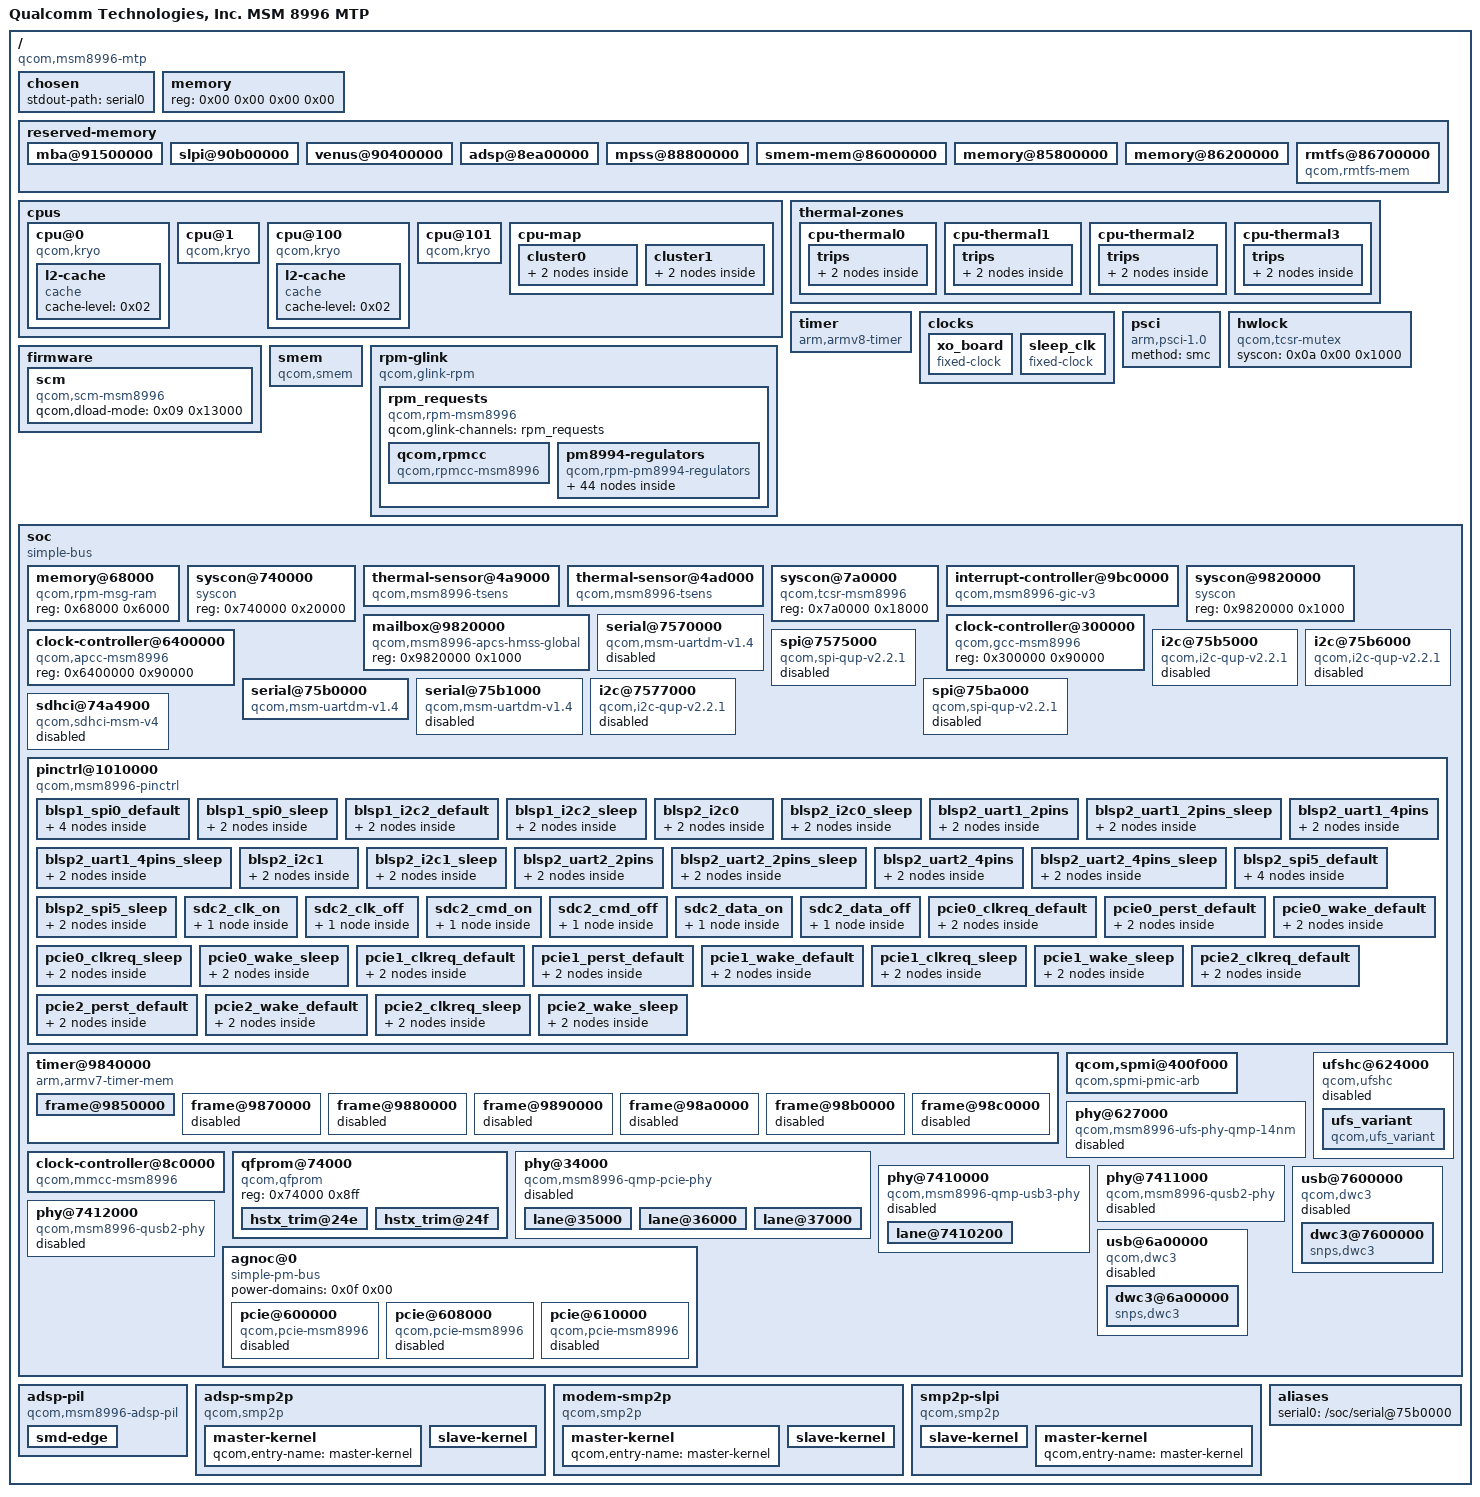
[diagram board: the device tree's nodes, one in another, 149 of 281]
/dts-v1/;

/ {
	model = "Qualcomm Technologies, Inc. MSM 8996 MTP";
	interrupt-parent = <0x01>;
	#address-cells = <0x02>;
	#size-cells = <0x02>;
	compatible = "qcom,msm8996-mtp";

	chosen {
		stdout-path = "serial0";
	};

	memory {
		device_type = "memory";
		reg = <0x00 0x00 0x00 0x00>;
	};

	reserved-memory {
		#address-cells = <0x02>;
		#size-cells = <0x02>;
		ranges;

		mba@91500000 {
			reg = <0x00 0x91500000 0x00 0x200000>;
			no-map;
		};

		slpi@90b00000 {
			reg = <0x00 0x90b00000 0x00 0xa00000>;
			no-map;
		};

		venus@90400000 {
			reg = <0x00 0x90400000 0x00 0x700000>;
			no-map;
		};

		adsp@8ea00000 {
			reg = <0x00 0x8ea00000 0x00 0x1a00000>;
			no-map;
			phandle = <0x3c>;
		};

		mpss@88800000 {
			reg = <0x00 0x88800000 0x00 0x6200000>;
			no-map;
		};

		smem-mem@86000000 {
			reg = <0x00 0x86000000 0x00 0x200000>;
			no-map;
			phandle = <0x0b>;
		};

		memory@85800000 {
			reg = <0x00 0x85800000 0x00 0x800000>;
			no-map;
		};

		memory@86200000 {
			reg = <0x00 0x86200000 0x00 0x2600000>;
			no-map;
		};

		rmtfs@86700000 {
			compatible = "qcom,rmtfs-mem";
			size = <0x00 0x200000>;
			alloc-ranges = <0x00 0xa0000000 0x00 0x2000000>;
			no-map;
			qcom,client-id = <0x01>;
			qcom,vmid = <0x0f>;
		};
	};

	cpus {
		#address-cells = <0x02>;
		#size-cells = <0x00>;

		cpu@0 {
			device_type = "cpu";
			compatible = "qcom,kryo";
			reg = <0x00 0x00>;
			enable-method = "psci";
			next-level-cache = <0x02>;
			phandle = <0x04>;

			l2-cache {
				compatible = "cache";
				cache-level = <0x02>;
				phandle = <0x02>;
			};
		};

		cpu@1 {
			device_type = "cpu";
			compatible = "qcom,kryo";
			reg = <0x00 0x01>;
			enable-method = "psci";
			next-level-cache = <0x02>;
			phandle = <0x05>;
		};

		cpu@100 {
			device_type = "cpu";
			compatible = "qcom,kryo";
			reg = <0x00 0x100>;
			enable-method = "psci";
			next-level-cache = <0x03>;
			phandle = <0x06>;

			l2-cache {
				compatible = "cache";
				cache-level = <0x02>;
				phandle = <0x03>;
			};
		};

		cpu@101 {
			device_type = "cpu";
			compatible = "qcom,kryo";
			reg = <0x00 0x101>;
			enable-method = "psci";
			next-level-cache = <0x03>;
			phandle = <0x07>;
		};

		cpu-map {

			cluster0 {

				core0 {
					cpu = <0x04>;
				};

				core1 {
					cpu = <0x05>;
				};
			};

			cluster1 {

				core0 {
					cpu = <0x06>;
				};

				core1 {
					cpu = <0x07>;
				};
			};
		};
	};

	thermal-zones {

		cpu-thermal0 {
			polling-delay-passive = <0xfa>;
			polling-delay = <0x3e8>;
			thermal-sensors = <0x08 0x03>;

			trips {

				trip0 {
					temperature = <0x124f8>;
					hysteresis = <0x7d0>;
					type = "passive";
				};

				trip1 {
					temperature = <0x1adb0>;
					hysteresis = <0x7d0>;
					type = "critical";
				};
			};
		};

		cpu-thermal1 {
			polling-delay-passive = <0xfa>;
			polling-delay = <0x3e8>;
			thermal-sensors = <0x08 0x05>;

			trips {

				trip0 {
					temperature = <0x124f8>;
					hysteresis = <0x7d0>;
					type = "passive";
				};

				trip1 {
					temperature = <0x1adb0>;
					hysteresis = <0x7d0>;
					type = "critical";
				};
			};
		};

		cpu-thermal2 {
			polling-delay-passive = <0xfa>;
			polling-delay = <0x3e8>;
			thermal-sensors = <0x08 0x08>;

			trips {

				trip0 {
					temperature = <0x124f8>;
					hysteresis = <0x7d0>;
					type = "passive";
				};

				trip1 {
					temperature = <0x1adb0>;
					hysteresis = <0x7d0>;
					type = "critical";
				};
			};
		};

		cpu-thermal3 {
			polling-delay-passive = <0xfa>;
			polling-delay = <0x3e8>;
			thermal-sensors = <0x08 0x0a>;

			trips {

				trip0 {
					temperature = <0x124f8>;
					hysteresis = <0x7d0>;
					type = "passive";
				};

				trip1 {
					temperature = <0x1adb0>;
					hysteresis = <0x7d0>;
					type = "critical";
				};
			};
		};
	};

	timer {
		compatible = "arm,armv8-timer";
		interrupts = <0x01 0x0d 0x08 0x01 0x0e 0x08 0x01 0x0b 0x08 0x01 0x0a 0x08>;
	};

	clocks {

		xo_board {
			compatible = "fixed-clock";
			#clock-cells = <0x00>;
			clock-frequency = <0x124f800>;
			clock-output-names = "xo_board";
			phandle = <0x1a>;
		};

		sleep_clk {
			compatible = "fixed-clock";
			#clock-cells = <0x00>;
			clock-frequency = <0x7ffc>;
			clock-output-names = "sleep_clk";
		};
	};

	psci {
		compatible = "arm,psci-1.0";
		method = "smc";
	};

	firmware {

		scm {
			compatible = "qcom,scm-msm8996";
			qcom,dload-mode = <0x09 0x13000>;
		};
	};

	hwlock {
		compatible = "qcom,tcsr-mutex";
		syscon = <0x0a 0x00 0x1000>;
		#hwlock-cells = <0x01>;
		phandle = <0x0c>;
	};

	smem {
		compatible = "qcom,smem";
		memory-region = <0x0b>;
		hwlocks = <0x0c 0x03>;
	};

	rpm-glink {
		compatible = "qcom,glink-rpm";
		interrupts = <0x00 0xa8 0x01>;
		qcom,rpm-msg-ram = <0x0d>;
		mboxes = <0x0e 0x00>;

		rpm_requests {
			compatible = "qcom,rpm-msm8996";
			qcom,glink-channels = "rpm_requests";

			qcom,rpmcc {
				compatible = "qcom,rpmcc-msm8996";
				#clock-cells = <0x01>;
				phandle = <0x1e>;
			};

			pm8994-regulators {
				compatible = "qcom,rpm-pm8994-regulators";

				s1 {
				};

				s2 {
				};

				s3 {
				};

				s4 {
					phandle = <0x21>;
				};

				s5 {
				};

				s6 {
				};

				s7 {
				};

				s8 {
				};

				s9 {
				};

				s10 {
				};

				s11 {
				};

				s12 {
				};

				l1 {
				};

				l2 {
				};

				l3 {
				};

				l4 {
				};

				l5 {
				};

				l6 {
				};

				l7 {
				};

				l8 {
				};

				l9 {
				};

				l10 {
				};

				l11 {
				};

				l12 {
					phandle = <0x1c>;
				};

				l13 {
				};

				l14 {
				};

				l15 {
				};

				l16 {
				};

				l17 {
				};

				l18 {
				};

				l19 {
				};

				l20 {
					phandle = <0x20>;
				};

				l21 {
				};

				l22 {
				};

				l23 {
				};

				l24 {
					phandle = <0x23>;
				};

				l25 {
					phandle = <0x1d>;
				};

				l26 {
				};

				l27 {
				};

				l28 {
					phandle = <0x1b>;
				};

				l29 {
				};

				l30 {
				};

				l31 {
				};

				l32 {
				};
			};
		};
	};

	soc {
		#address-cells = <0x01>;
		#size-cells = <0x01>;
		ranges = <0x00 0x00 0x00 0xffffffff>;
		compatible = "simple-bus";

		memory@68000 {
			compatible = "qcom,rpm-msg-ram";
			reg = <0x68000 0x6000>;
			phandle = <0x0d>;
		};

		syscon@740000 {
			compatible = "syscon";
			reg = <0x740000 0x20000>;
			phandle = <0x0a>;
		};

		thermal-sensor@4a9000 {
			compatible = "qcom,msm8996-tsens";
			reg = <0x4a9000 0x1000 0x4a8000 0x1000>;
			#qcom,sensors = <0x0d>;
			#thermal-sensor-cells = <0x01>;
			phandle = <0x08>;
		};

		thermal-sensor@4ad000 {
			compatible = "qcom,msm8996-tsens";
			reg = <0x4ad000 0x1000 0x4ac000 0x1000>;
			#qcom,sensors = <0x08>;
			#thermal-sensor-cells = <0x01>;
		};

		syscon@7a0000 {
			compatible = "qcom,tcsr-msm8996\0syscon";
			reg = <0x7a0000 0x18000>;
			phandle = <0x09>;
		};

		interrupt-controller@9bc0000 {
			compatible = "qcom,msm8996-gic-v3\0arm,gic-v3";
			#interrupt-cells = <0x03>;
			interrupt-controller;
			#redistributor-regions = <0x01>;
			redistributor-stride = <0x00 0x40000>;
			reg = <0x9bc0000 0x10000 0x9c00000 0x100000>;
			interrupts = <0x01 0x09 0x04>;
			phandle = <0x01>;
		};

		syscon@9820000 {
			compatible = "syscon";
			reg = <0x9820000 0x1000>;
			phandle = <0x3e>;
		};

		mailbox@9820000 {
			compatible = "qcom,msm8996-apcs-hmss-global";
			reg = <0x9820000 0x1000>;
			#mbox-cells = <0x01>;
			phandle = <0x0e>;
		};

		clock-controller@300000 {
			compatible = "qcom,gcc-msm8996";
			#clock-cells = <0x01>;
			#reset-cells = <0x01>;
			#power-domain-cells = <0x01>;
			reg = <0x300000 0x90000>;
			phandle = <0x0f>;
		};

		clock-controller@6400000 {
			compatible = "qcom,apcc-msm8996";
			reg = <0x6400000 0x90000>;
			#clock-cells = <0x01>;
		};

		serial@7570000 {
			compatible = "qcom,msm-uartdm-v1.4\0qcom,msm-uartdm";
			reg = <0x7570000 0x1000>;
			interrupts = <0x00 0x6c 0x04>;
			clocks = <0x0f 0x74 0x0f 0x6d>;
			clock-names = "core\0iface";
			status = "disabled";
		};

		spi@7575000 {
			compatible = "qcom,spi-qup-v2.2.1";
			reg = <0x7575000 0x600>;
			interrupts = <0x00 0x5f 0x04>;
			clocks = <0x0f 0x6f 0x0f 0x6d>;
			clock-names = "core\0iface";
			pinctrl-names = "default\0sleep";
			pinctrl-0 = <0x10>;
			pinctrl-1 = <0x11>;
			#address-cells = <0x01>;
			#size-cells = <0x00>;
			status = "disabled";
		};

		i2c@75b5000 {
			compatible = "qcom,i2c-qup-v2.2.1";
			reg = <0x75b5000 0x1000>;
			interrupts = <0x00 0x65 0x04>;
			clocks = <0x0f 0x81 0x0f 0x84>;
			clock-names = "iface\0core";
			pinctrl-names = "default\0sleep";
			pinctrl-0 = <0x12>;
			pinctrl-1 = <0x13>;
			#address-cells = <0x01>;
			#size-cells = <0x00>;
			status = "disabled";
		};

		serial@75b0000 {
			compatible = "qcom,msm-uartdm-v1.4\0qcom,msm-uartdm";
			reg = <0x75b0000 0x1000>;
			interrupts = <0x00 0x72 0x04>;
			clocks = <0x0f 0x88 0x0f 0x81>;
			clock-names = "core\0iface";
			status = "okay";
		};

		i2c@75b6000 {
			compatible = "qcom,i2c-qup-v2.2.1";
			reg = <0x75b6000 0x1000>;
			interrupts = <0x00 0x66 0x04>;
			clocks = <0x0f 0x81 0x0f 0x87>;
			clock-names = "iface\0core";
			pinctrl-names = "default\0sleep";
			pinctrl-0 = <0x14>;
			pinctrl-1 = <0x15>;
			#address-cells = <0x01>;
			#size-cells = <0x00>;
			status = "disabled";
		};

		serial@75b1000 {
			compatible = "qcom,msm-uartdm-v1.4\0qcom,msm-uartdm";
			reg = <0x75b1000 0x1000>;
			interrupts = <0x00 0x73 0x04>;
			clocks = <0x0f 0x8b 0x0f 0x81>;
			clock-names = "core\0iface";
			status = "disabled";
		};

		i2c@7577000 {
			compatible = "qcom,i2c-qup-v2.2.1";
			reg = <0x7577000 0x1000>;
			interrupts = <0x00 0x61 0x04>;
			clocks = <0x0f 0x6d 0x0f 0x76>;
			clock-names = "iface\0core";
			pinctrl-names = "default\0sleep";
			pinctrl-0 = <0x16>;
			pinctrl-1 = <0x17>;
			#address-cells = <0x01>;
			#size-cells = <0x00>;
			status = "disabled";
		};

		spi@75ba000 {
			compatible = "qcom,spi-qup-v2.2.1";
			reg = <0x75ba000 0x600>;
			interrupts = <0x00 0x6a 0x04>;
			clocks = <0x0f 0x92 0x0f 0x81>;
			clock-names = "core\0iface";
			pinctrl-names = "default\0sleep";
			pinctrl-0 = <0x18>;
			pinctrl-1 = <0x19>;
			#address-cells = <0x01>;
			#size-cells = <0x00>;
			status = "disabled";
		};

		sdhci@74a4900 {
			status = "disabled";
			compatible = "qcom,sdhci-msm-v4";
			reg = <0x74a4900 0x314 0x74a4000 0x800>;
			reg-names = "hc_mem\0core_mem";
			interrupts = <0x00 0x7d 0x04 0x00 0xdd 0x04>;
			interrupt-names = "hc_irq\0pwr_irq";
			clock-names = "iface\0core\0xo";
			clocks = <0x0f 0x68 0x0f 0x67 0x1a>;
			bus-width = <0x04>;
		};

		pinctrl@1010000 {
			compatible = "qcom,msm8996-pinctrl";
			reg = <0x1010000 0x300000>;
			interrupts = <0x00 0xd0 0x04>;
			gpio-controller;
			#gpio-cells = <0x02>;
			interrupt-controller;
			#interrupt-cells = <0x02>;

			blsp1_spi0_default {
				phandle = <0x10>;

				pinmux {
					function = "blsp_spi1";
					pins = "gpio0\0gpio1\0gpio3";
				};

				pinmux_cs {
					function = "gpio";
					pins = "gpio2";
				};

				pinconf {
					pins = "gpio0\0gpio1\0gpio3";
					drive-strength = <0x0c>;
					bias-disable;
				};

				pinconf_cs {
					pins = "gpio2";
					drive-strength = <0x10>;
					bias-disable;
					output-high;
				};
			};

			blsp1_spi0_sleep {
				phandle = <0x11>;

				pinmux {
					function = "gpio";
					pins = "gpio0\0gpio1\0gpio2\0gpio3";
				};

				pinconf {
					pins = "gpio0\0gpio1\0gpio2\0gpio3";
					drive-strength = <0x02>;
					bias-pull-down;
				};
			};

			blsp1_i2c2_default {
				phandle = <0x16>;

				pinmux {
					function = "blsp_i2c3";
					pins = "gpio47\0gpio48";
				};

				pinconf {
					pins = "gpio47\0gpio48";
					drive-strength = <0x10>;
					bias-disable = <0x00>;
				};
			};

			blsp1_i2c2_sleep {
				phandle = <0x17>;

				pinmux {
					function = "gpio";
					pins = "gpio47\0gpio48";
				};

				pinconf {
					pins = "gpio47\0gpio48";
					drive-strength = <0x02>;
					bias-disable = <0x00>;
				};
			};

			blsp2_i2c0 {
				phandle = <0x12>;

				pinmux {
					function = "blsp_i2c7";
					pins = "gpio55\0gpio56";
				};

				pinconf {
					pins = "gpio55\0gpio56";
					drive-strength = <0x10>;
					bias-disable;
				};
			};

			blsp2_i2c0_sleep {
				phandle = <0x13>;

				pinmux {
					function = "gpio";
					pins = "gpio55\0gpio56";
				};

				pinconf {
					pins = "gpio55\0gpio56";
					drive-strength = <0x02>;
					bias-disable;
				};
			};

			blsp2_uart1_2pins {

				pinmux {
					function = "blsp_uart8";
					pins = "gpio4\0gpio5";
				};

				pinconf {
					pins = "gpio4\0gpio5";
					drive-strength = <0x10>;
					bias-disable;
				};
			};

			blsp2_uart1_2pins_sleep {

				pinmux {
					function = "gpio";
					pins = "gpio4\0gpio5";
				};

				pinconf {
					pins = "gpio4\0gpio5";
					drive-strength = <0x02>;
					bias-disable;
				};
			};

			blsp2_uart1_4pins {

				pinmux {
					function = "blsp_uart8";
					pins = "gpio4\0gpio5\0gpio6\0gpio7";
				};

				pinconf {
					pins = "gpio4\0gpio5\0gpio6\0gpio7";
					drive-strength = <0x10>;
					bias-disable;
				};
			};

			blsp2_uart1_4pins_sleep {

				pinmux {
					function = "gpio";
					pins = "gpio4\0gpio5\0gpio6\0gpio7";
				};

				pinconf {
					pins = "gpio4\0gpiio5\0gpio6\0gpio7";
					drive-strength = <0x02>;
					bias-disable;
				};
			};

			blsp2_i2c1 {
				phandle = <0x14>;

				pinmux {
					function = "blsp_i2c8";
					pins = "gpio6\0gpio7";
				};

				pinconf {
					pins = "gpio6\0gpio7";
					drive-strength = <0x10>;
					bias-disable;
				};
			};

			blsp2_i2c1_sleep {
				phandle = <0x15>;

				pinmux {
					function = "gpio";
					pins = "gpio6\0gpio7";
				};

				pinconf {
					pins = "gpio6\0gpio7";
					drive-strength = <0x02>;
					bias-disable;
				};
			};

			blsp2_uart2_2pins {

				pinmux {
					function = "blsp_uart9";
					pins = "gpio49\0gpio50";
				};

				pinconf {
					pins = "gpio49\0gpio50";
					drive-strength = <0x10>;
					bias-disable;
				};
			};

			blsp2_uart2_2pins_sleep {

				pinmux {
					function = "gpio";
					pins = "gpio49\0gpio50";
				};

				pinconf {
					pins = "gpio49\0gpio50";
					drive-strength = <0x02>;
					bias-disable;
				};
			};

			blsp2_uart2_4pins {

				pinmux {
					function = "blsp_uart9";
					pins = "gpio49\0gpio50\0gpio51\0gpio52";
				};

				pinconf {
					pins = "gpio49\0gpio50\0gpio51\0gpio52";
					drive-strength = <0x10>;
					bias-disable;
				};
			};

			blsp2_uart2_4pins_sleep {

				pinmux {
					function = "gpio";
					pins = "gpio49\0gpio50\0gpio51\0gpio52";
				};

				pinconf {
					pins = "gpio49\0gpio50\0gpio51\0gpio52";
					drive-strength = <0x02>;
					bias-disable;
				};
			};

			blsp2_spi5_default {
				phandle = <0x18>;

				pinmux {
					function = "blsp_spi12";
					pins = "gpio85\0gpio86\0gpio88";
				};

				pinmux_cs {
					function = "gpio";
					pins = "gpio87";
				};

				pinconf {
					pins = "gpio85\0gpio86\0gpio88";
					drive-strength = <0x0c>;
					bias-disable;
				};

				pinconf_cs {
					pins = "gpio87";
					drive-strength = <0x10>;
					bias-disable;
					output-high;
				};
			};

			blsp2_spi5_sleep {
				phandle = <0x19>;

				pinmux {
					function = "gpio";
					pins = "gpio85\0gpio86\0gpio87\0gpio88";
				};

				pinconf {
					pins = "gpio85\0gpio86\0gpio87\0gpio88";
					drive-strength = <0x02>;
					bias-pull-down;
				};
			};

			sdc2_clk_on {

				config {
					pins = "sdc2_clk";
					bias-disable;
					drive-strength = <0x10>;
				};
			};

			sdc2_clk_off {

				config {
					pins = "sdc2_clk";
					bias-disable;
					drive-strength = <0x02>;
				};
			};

			sdc2_cmd_on {

				config {
					pins = "sdc2_cmd";
					bias-pull-up;
					drive-strength = <0x0a>;
				};
			};

			sdc2_cmd_off {

				config {
					pins = "sdc2_cmd";
					bias-pull-up;
					drive-strength = <0x02>;
				};
			};

			sdc2_data_on {

				config {
					pins = "sdc2_data";
					bias-pull-up;
					drive-strength = <0x0a>;
				};
			};

			sdc2_data_off {

				config {
					pins = "sdc2_data";
					bias-pull-up;
					drive-strength = <0x02>;
				};
			};

			pcie0_clkreq_default {
				phandle = <0x2a>;

				mux {
					pins = "gpio36";
					function = "pci_e0";
				};

				config {
					pins = "gpio36";
					drive-strength = <0x02>;
					bias-pull-up;
				};
			};

			pcie0_perst_default {
				phandle = <0x2b>;

				mux {
					pins = "gpio35";
					function = "gpio";
				};

				config {
					pins = "gpio35";
					drive-strength = <0x02>;
					bias-pull-down;
				};
			};

			pcie0_wake_default {
				phandle = <0x2c>;

				mux {
					pins = "gpio37";
					function = "gpio";
				};

				config {
					pins = "gpio37";
					drive-strength = <0x02>;
					bias-pull-up;
				};
			};

			pcie0_clkreq_sleep {
				phandle = <0x2d>;

				mux {
					pins = "gpio36";
					function = "gpio";
				};

				config {
					pins = "gpio36";
					drive-strength = <0x02>;
					bias-disable;
				};
			};

			pcie0_wake_sleep {
				phandle = <0x2e>;

				mux {
					pins = "gpio37";
					function = "gpio";
				};

				config {
					pins = "gpio37";
					drive-strength = <0x02>;
					bias-disable;
				};
			};

			pcie1_clkreq_default {
				phandle = <0x30>;

				mux {
					pins = "gpio131";
					function = "pci_e1";
				};

				config {
					pins = "gpio131";
					drive-strength = <0x02>;
					bias-pull-up;
				};
			};

			pcie1_perst_default {
				phandle = <0x31>;

				mux {
					pins = "gpio130";
					function = "gpio";
				};

				config {
					pins = "gpio130";
					drive-strength = <0x02>;
					bias-pull-down;
				};
			};

			pcie1_wake_default {
				phandle = <0x32>;

				mux {
					pins = "gpio132";
					function = "gpio";
				};

				config {
					pins = "gpio132";
					drive-strength = <0x02>;
					bias-pull-down;
				};
			};

			pcie1_clkreq_sleep {
				phandle = <0x33>;

				mux {
					pins = "gpio131";
					function = "gpio";
				};

				config {
					pins = "gpio131";
					drive-strength = <0x02>;
					bias-disable;
				};
			};

			pcie1_wake_sleep {
				phandle = <0x34>;

				mux {
					pins = "gpio132";
					function = "gpio";
				};

				config {
					pins = "gpio132";
					drive-strength = <0x02>;
					bias-disable;
				};
			};

			pcie2_clkreq_default {
				phandle = <0x36>;

				mux {
					pins = "gpio115";
					function = "pci_e2";
				};

				config {
					pins = "gpio115";
					drive-strength = <0x02>;
					bias-pull-up;
				};
			};

			pcie2_perst_default {
				phandle = <0x37>;

				mux {
					pins = "gpio114";
					function = "gpio";
				};

				config {
					pins = "gpio114";
					drive-strength = <0x02>;
					bias-pull-down;
				};
			};

			pcie2_wake_default {
				phandle = <0x38>;

				mux {
					pins = "gpio116";
					function = "gpio";
				};

				config {
					pins = "gpio116";
					drive-strength = <0x02>;
					bias-pull-down;
				};
			};

			pcie2_clkreq_sleep {
				phandle = <0x39>;

				mux {
					pins = "gpio115";
					function = "gpio";
				};

				config {
					pins = "gpio115";
					drive-strength = <0x02>;
					bias-disable;
				};
			};

			pcie2_wake_sleep {
				phandle = <0x3a>;

				mux {
					pins = "gpio116";
					function = "gpio";
				};

				config {
					pins = "gpio116";
					drive-strength = <0x02>;
					bias-disable;
				};
			};
		};

		timer@9840000 {
			#address-cells = <0x01>;
			#size-cells = <0x01>;
			ranges;
			compatible = "arm,armv7-timer-mem";
			reg = <0x9840000 0x1000>;
			clock-frequency = <0x124f800>;

			frame@9850000 {
				frame-number = <0x00>;
				interrupts = <0x00 0x1f 0x04 0x00 0x1e 0x04>;
				reg = <0x9850000 0x1000 0x9860000 0x1000>;
			};

			frame@9870000 {
				frame-number = <0x01>;
				interrupts = <0x00 0x20 0x04>;
				reg = <0x9870000 0x1000>;
				status = "disabled";
			};

			frame@9880000 {
				frame-number = <0x02>;
				interrupts = <0x00 0x21 0x04>;
				reg = <0x9880000 0x1000>;
				status = "disabled";
			};

			frame@9890000 {
				frame-number = <0x03>;
				interrupts = <0x00 0x22 0x04>;
				reg = <0x9890000 0x1000>;
				status = "disabled";
			};

			frame@98a0000 {
				frame-number = <0x04>;
				interrupts = <0x00 0x23 0x04>;
				reg = <0x98a0000 0x1000>;
				status = "disabled";
			};

			frame@98b0000 {
				frame-number = <0x05>;
				interrupts = <0x00 0x24 0x04>;
				reg = <0x98b0000 0x1000>;
				status = "disabled";
			};

			frame@98c0000 {
				frame-number = <0x06>;
				interrupts = <0x00 0x25 0x04>;
				reg = <0x98c0000 0x1000>;
				status = "disabled";
			};
		};

		qcom,spmi@400f000 {
			compatible = "qcom,spmi-pmic-arb";
			reg = <0x400f000 0x1000 0x4400000 0x800000 0x4c00000 0x800000 0x5800000 0x200000 0x400a000 0x2100>;
			reg-names = "core\0chnls\0obsrvr\0intr\0cnfg";
			interrupt-names = "periph_irq";
			interrupts = <0x00 0x146 0x04>;
			qcom,ee = <0x00>;
			qcom,channel = <0x00>;
			#address-cells = <0x02>;
			#size-cells = <0x00>;
			interrupt-controller;
			#interrupt-cells = <0x04>;
		};

		phy@627000 {
			compatible = "qcom,msm8996-ufs-phy-qmp-14nm";
			reg = <0x627000 0xda8>;
			reg-names = "phy_mem";
			#phy-cells = <0x00>;
			vdda-phy-supply = <0x1b>;
			vdda-pll-supply = <0x1c>;
			vdda-phy-max-microamp = <0x47cc>;
			vdda-pll-max-microamp = <0x24e0>;
			vddp-ref-clk-supply = <0x1d>;
			vddp-ref-clk-max-microamp = <0x64>;
			vddp-ref-clk-always-on;
			clock-names = "ref_clk_src\0ref_clk";
			clocks = <0x1e 0x54 0x0f 0xd7>;
			status = "disabled";
			phandle = <0x1f>;
		};

		ufshc@624000 {
			compatible = "qcom,ufshc";
			reg = <0x624000 0x2500>;
			interrupts = <0x00 0x109 0x04>;
			phys = <0x1f>;
			phy-names = "ufsphy";
			vcc-supply = <0x20>;
			vccq-supply = <0x1d>;
			vccq2-supply = <0x21>;
			vcc-max-microamp = <0x927c0>;
			vccq-max-microamp = <0x6ddd0>;
			vccq2-max-microamp = <0x6ddd0>;
			power-domains = <0x0f 0x08>;
			clock-names = "core_clk_src\0core_clk\0bus_clk\0bus_aggr_clk\0iface_clk\0core_clk_unipro_src\0core_clk_unipro\0core_clk_ice\0ref_clk\0tx_lane0_sync_clk\0rx_lane0_sync_clk";
			clocks = <0x0f 0x49 0x0f 0xc1 0x0f 0x52 0x0f 0xd1 0x0f 0xc2 0x0f 0x4a 0x0f 0xc8 0x0f 0xc9 0x1e 0x54 0x0f 0xc5 0x0f 0xc6>;
			freq-table-hz = <0x5f5e100 0xbebc200 0x00 0x00 0x00 0x00 0x00 0x00 0x00 0x00 0x8f0d180 0x11e1a300 0x00 0x00 0x00 0x00 0x00 0x00 0x00 0x00 0x00 0x00>;
			lanes-per-direction = <0x01>;
			status = "disabled";

			ufs_variant {
				compatible = "qcom,ufs_variant";
			};
		};

		clock-controller@8c0000 {
			compatible = "qcom,mmcc-msm8996";
			#clock-cells = <0x01>;
			#reset-cells = <0x01>;
			#power-domain-cells = <0x01>;
			reg = <0x8c0000 0x40000>;
			assigned-clocks = <0x22 0x0f 0x22 0x03 0x22 0x07 0x22 0x09 0x22 0x0b>;
			assigned-clock-rates = <0x25317c00 0x30479e80 0x3a699d00 0x39387000 0x312c8040>;
			phandle = <0x22>;
		};

		qfprom@74000 {
			compatible = "qcom,qfprom";
			reg = <0x74000 0x8ff>;
			#address-cells = <0x01>;
			#size-cells = <0x01>;

			hstx_trim@24e {
				reg = <0x24e 0x02>;
				bits = <0x05 0x04>;
				phandle = <0x24>;
			};

			hstx_trim@24f {
				reg = <0x24f 0x01>;
				bits = <0x01 0x04>;
				phandle = <0x25>;
			};
		};

		phy@34000 {
			compatible = "qcom,msm8996-qmp-pcie-phy";
			reg = <0x34000 0x488>;
			#clock-cells = <0x01>;
			#address-cells = <0x01>;
			#size-cells = <0x01>;
			ranges;
			clocks = <0x0f 0xc0 0x0f 0xbf 0x0f 0xd8>;
			clock-names = "aux\0cfg_ahb\0ref";
			vdda-phy-supply = <0x1b>;
			vdda-pll-supply = <0x1c>;
			resets = <0x0f 0x55 0x0f 0x65 0x0f 0x66>;
			reset-names = "phy\0common\0cfg";
			status = "disabled";

			lane@35000 {
				reg = <0x35000 0x130 0x35200 0x200 0x35400 0x1dc>;
				#phy-cells = <0x00>;
				clock-output-names = "pcie_0_pipe_clk_src";
				clocks = <0x0f 0xb4>;
				clock-names = "pipe0";
				resets = <0x0f 0x50>;
				reset-names = "lane0";
				phandle = <0x29>;
			};

			lane@36000 {
				reg = <0x36000 0x130 0x36200 0x200 0x36400 0x1dc>;
				#phy-cells = <0x00>;
				clock-output-names = "pcie_1_pipe_clk_src";
				clocks = <0x0f 0xb9>;
				clock-names = "pipe1";
				resets = <0x0f 0x52>;
				reset-names = "lane1";
				phandle = <0x2f>;
			};

			lane@37000 {
				reg = <0x37000 0x130 0x37200 0x200 0x37400 0x1dc>;
				#phy-cells = <0x00>;
				clock-output-names = "pcie_2_pipe_clk_src";
				clocks = <0x0f 0xbe>;
				clock-names = "pipe2";
				resets = <0x0f 0x54>;
				reset-names = "lane2";
				phandle = <0x35>;
			};
		};

		phy@7410000 {
			compatible = "qcom,msm8996-qmp-usb3-phy";
			reg = <0x7410000 0x1c4>;
			#clock-cells = <0x01>;
			#address-cells = <0x01>;
			#size-cells = <0x01>;
			ranges;
			clocks = <0x0f 0x5e 0x0f 0x63 0x0f 0xd5>;
			clock-names = "aux\0cfg_ahb\0ref";
			vdda-phy-supply = <0x1b>;
			vdda-pll-supply = <0x1c>;
			resets = <0x0f 0x67 0x0f 0x68>;
			reset-names = "phy\0common";
			status = "disabled";

			lane@7410200 {
				reg = <0x7410200 0x200 0x7410400 0x130 0x7410600 0x1a8>;
				#phy-cells = <0x00>;
				clock-output-names = "usb3_phy_pipe_clk_src";
				clocks = <0x0f 0x5f>;
				clock-names = "pipe0";
				phandle = <0x28>;
			};
		};

		phy@7411000 {
			compatible = "qcom,msm8996-qusb2-phy";
			reg = <0x7411000 0x180>;
			#phy-cells = <0x00>;
			clocks = <0x0f 0x63 0x0f 0xda>;
			clock-names = "cfg_ahb\0ref";
			vdda-pll-supply = <0x1c>;
			vdda-phy-dpdm-supply = <0x23>;
			resets = <0x0f 0x09>;
			nvmem-cells = <0x24>;
			status = "disabled";
			phandle = <0x27>;
		};

		phy@7412000 {
			compatible = "qcom,msm8996-qusb2-phy";
			reg = <0x7412000 0x180>;
			#phy-cells = <0x00>;
			clocks = <0x0f 0x63 0x0f 0xd9>;
			clock-names = "cfg_ahb\0ref";
			vdda-pll-supply = <0x1c>;
			vdda-phy-dpdm-supply = <0x23>;
			resets = <0x0f 0x0a>;
			nvmem-cells = <0x25>;
			status = "disabled";
			phandle = <0x26>;
		};

		usb@7600000 {
			compatible = "qcom,dwc3";
			#address-cells = <0x01>;
			#size-cells = <0x01>;
			ranges;
			clocks = <0x0f 0x55 0x0f 0x60 0x0f 0x62 0x0f 0x61 0x0f 0x63>;
			assigned-clocks = <0x0f 0x62 0x0f 0x60>;
			assigned-clock-rates = <0x124f800 0x3938700>;
			power-domains = <0x0f 0x04>;
			status = "disabled";

			dwc3@7600000 {
				compatible = "snps,dwc3";
				reg = <0x7600000 0xcc00>;
				interrupts = <0x00 0x8a 0x04>;
				phys = <0x26>;
				phy-names = "usb2-phy";
				snps,dis_u2_susphy_quirk;
				snps,dis_enblslpm_quirk;
			};
		};

		usb@6a00000 {
			compatible = "qcom,dwc3";
			#address-cells = <0x01>;
			#size-cells = <0x01>;
			ranges;
			clocks = <0x0f 0x51 0x0f 0x5b 0x0f 0xd2 0x0f 0x5d 0x0f 0x5c 0x0f 0x63>;
			assigned-clocks = <0x0f 0x5d 0x0f 0x5b>;
			assigned-clock-rates = <0x124f800 0x7270e00>;
			power-domains = <0x0f 0x04>;
			status = "disabled";

			dwc3@6a00000 {
				compatible = "snps,dwc3";
				reg = <0x6a00000 0xcc00>;
				interrupts = <0x00 0x83 0x04>;
				phys = <0x27 0x28>;
				phy-names = "usb2-phy\0usb3-phy";
				snps,dis_u2_susphy_quirk;
				snps,dis_enblslpm_quirk;
			};
		};

		agnoc@0 {
			power-domains = <0x0f 0x00>;
			compatible = "simple-pm-bus";
			#address-cells = <0x01>;
			#size-cells = <0x01>;
			ranges;

			pcie@600000 {
				compatible = "qcom,pcie-msm8996\0snps,dw-pcie";
				status = "disabled";
				power-domains = <0x0f 0x05>;
				bus-range = <0x00 0xff>;
				num-lanes = <0x01>;
				reg = <0x600000 0x2000 0xc000000 0xf1d 0xc000f20 0xa8 0xc100000 0x100000>;
				reg-names = "parf\0dbi\0elbi\0config";
				phys = <0x29>;
				phy-names = "pciephy";
				#address-cells = <0x03>;
				#size-cells = <0x02>;
				ranges = <0x1000000 0x00 0xc200000 0xc200000 0x00 0x100000 0x2000000 0x00 0xc300000 0xc300000 0x00 0xd00000>;
				interrupts = <0x00 0x195 0x04>;
				interrupt-names = "msi";
				#interrupt-cells = <0x01>;
				interrupt-map-mask = <0x00 0x00 0x00 0x07>;
				interrupt-map = <0x00 0x00 0x00 0x01 0x01 0x00 0xf4 0x04 0x00 0x00 0x00 0x02 0x01 0x00 0xf5 0x04 0x00 0x00 0x00 0x03 0x01 0x00 0xf7 0x04 0x00 0x00 0x00 0x04 0x01 0x00 0xf8 0x04>;
				pinctrl-names = "default\0sleep";
				pinctrl-0 = <0x2a 0x2b 0x2c>;
				pinctrl-1 = <0x2d 0x2b 0x2e>;
				vdda-supply = <0x1b>;
				linux,pci-domain = <0x00>;
				clocks = <0x0f 0xb4 0x0f 0xb3 0x0f 0xb2 0x0f 0xb1 0x0f 0xb0>;
				clock-names = "pipe\0aux\0cfg\0bus_master\0bus_slave";
			};

			pcie@608000 {
				compatible = "qcom,pcie-msm8996\0snps,dw-pcie";
				power-domains = <0x0f 0x06>;
				bus-range = <0x00 0xff>;
				num-lanes = <0x01>;
				status = "disabled";
				reg = <0x608000 0x2000 0xd000000 0xf1d 0xd000f20 0xa8 0xd100000 0x100000>;
				reg-names = "parf\0dbi\0elbi\0config";
				phys = <0x2f>;
				phy-names = "pciephy";
				#address-cells = <0x03>;
				#size-cells = <0x02>;
				ranges = <0x1000000 0x00 0xd200000 0xd200000 0x00 0x100000 0x2000000 0x00 0xd300000 0xd300000 0x00 0xd00000>;
				interrupts = <0x00 0x19d 0x04>;
				interrupt-names = "msi";
				#interrupt-cells = <0x01>;
				interrupt-map-mask = <0x00 0x00 0x00 0x07>;
				interrupt-map = <0x00 0x00 0x00 0x01 0x01 0x00 0x110 0x04 0x00 0x00 0x00 0x02 0x01 0x00 0x111 0x04 0x00 0x00 0x00 0x03 0x01 0x00 0x112 0x04 0x00 0x00 0x00 0x04 0x01 0x00 0x113 0x04>;
				pinctrl-names = "default\0sleep";
				pinctrl-0 = <0x30 0x31 0x32>;
				pinctrl-1 = <0x33 0x31 0x34>;
				vdda-supply = <0x1b>;
				linux,pci-domain = <0x01>;
				clocks = <0x0f 0xb9 0x0f 0xb8 0x0f 0xb7 0x0f 0xb6 0x0f 0xb5>;
				clock-names = "pipe\0aux\0cfg\0bus_master\0bus_slave";
			};

			pcie@610000 {
				compatible = "qcom,pcie-msm8996\0snps,dw-pcie";
				power-domains = <0x0f 0x07>;
				bus-range = <0x00 0xff>;
				num-lanes = <0x01>;
				status = "disabled";
				reg = <0x610000 0x2000 0xe000000 0xf1d 0xe000f20 0xa8 0xe100000 0x100000>;
				reg-names = "parf\0dbi\0elbi\0config";
				phys = <0x35>;
				phy-names = "pciephy";
				#address-cells = <0x03>;
				#size-cells = <0x02>;
				ranges = <0x1000000 0x00 0xe200000 0xe200000 0x00 0x100000 0x2000000 0x00 0xe300000 0xe300000 0x00 0x1d00000>;
				device_type = "pci";
				interrupts = <0x00 0x1a5 0x04>;
				interrupt-names = "msi";
				#interrupt-cells = <0x01>;
				interrupt-map-mask = <0x00 0x00 0x00 0x07>;
				interrupt-map = <0x00 0x00 0x00 0x01 0x01 0x00 0x8e 0x04 0x00 0x00 0x00 0x02 0x01 0x00 0x8f 0x04 0x00 0x00 0x00 0x03 0x01 0x00 0x90 0x04 0x00 0x00 0x00 0x04 0x01 0x00 0x91 0x04>;
				pinctrl-names = "default\0sleep";
				pinctrl-0 = <0x36 0x37 0x38>;
				pinctrl-1 = <0x39 0x37 0x3a>;
				vdda-supply = <0x1b>;
				linux,pci-domain = <0x02>;
				clocks = <0x0f 0xbe 0x0f 0xbd 0x0f 0xbc 0x0f 0xbb 0x0f 0xba>;
				clock-names = "pipe\0aux\0cfg\0bus_master\0bus_slave";
			};
		};
	};

	adsp-pil {
		compatible = "qcom,msm8996-adsp-pil";
		interrupts-extended = <0x01 0x00 0xa2 0x01 0x3b 0x00 0x01 0x3b 0x01 0x01 0x3b 0x02 0x01 0x3b 0x03 0x01>;
		interrupt-names = "wdog\0fatal\0ready\0handover\0stop-ack";
		clocks = <0x1a>;
		clock-names = "xo";
		memory-region = <0x3c>;
		qcom,smem-states = <0x3d 0x00>;
		qcom,smem-state-names = "stop";

		smd-edge {
			interrupts = <0x00 0x9c 0x01>;
			label = "lpass";
			qcom,ipc = <0x3e 0x10 0x08>;
			qcom,smd-edge = <0x01>;
			qcom,remote-pid = <0x02>;
		};
	};

	adsp-smp2p {
		compatible = "qcom,smp2p";
		qcom,smem = <0x1bb 0x1ad>;
		interrupts = <0x00 0x9e 0x01>;
		qcom,ipc = <0x3e 0x10 0x0a>;
		qcom,local-pid = <0x00>;
		qcom,remote-pid = <0x02>;

		master-kernel {
			qcom,entry-name = "master-kernel";
			#qcom,smem-state-cells = <0x01>;
			phandle = <0x3d>;
		};

		slave-kernel {
			qcom,entry-name = "slave-kernel";
			interrupt-controller;
			#interrupt-cells = <0x02>;
			phandle = <0x3b>;
		};
	};

	modem-smp2p {
		compatible = "qcom,smp2p";
		qcom,smem = <0x1b3 0x1ac>;
		interrupts = <0x00 0x1c3 0x01>;
		qcom,ipc = <0x3e 0x10 0x0e>;
		qcom,local-pid = <0x00>;
		qcom,remote-pid = <0x01>;

		master-kernel {
			qcom,entry-name = "master-kernel";
			#qcom,smem-state-cells = <0x01>;
		};

		slave-kernel {
			qcom,entry-name = "slave-kernel";
			interrupt-controller;
			#interrupt-cells = <0x02>;
		};
	};

	smp2p-slpi {
		compatible = "qcom,smp2p";
		qcom,smem = <0x1e1 0x1ae>;
		interrupts = <0x00 0xb2 0x01>;
		qcom,ipc = <0x3e 0x10 0x1a>;
		qcom,local-pid = <0x00>;
		qcom,remote-pid = <0x03>;

		slave-kernel {
			qcom,entry-name = "slave-kernel";
			interrupt-controller;
			#interrupt-cells = <0x02>;
		};

		master-kernel {
			qcom,entry-name = "master-kernel";
			#qcom,smem-state-cells = <0x01>;
		};
	};

	aliases {
		serial0 = "/soc/serial@75b0000";
	};
};
